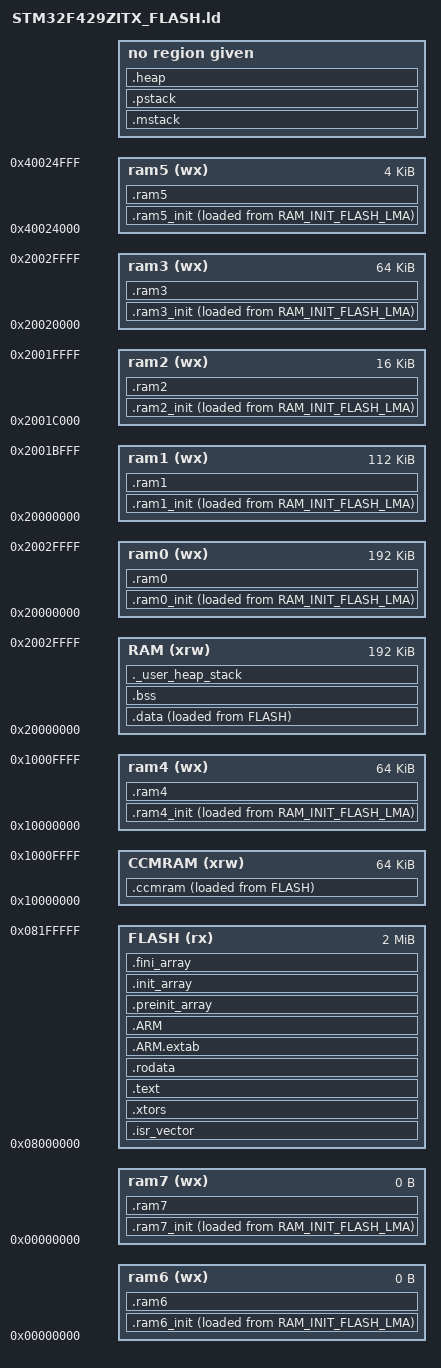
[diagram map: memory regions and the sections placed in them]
/*
******************************************************************************
**
** @file        : LinkerScript.ld
**
** @author      : Auto-generated by STM32CubeIDE
**
**  Abstract    : Linker script for NUCLEO-F429ZI Board embedding STM32F429ZITx Device from stm32f4 series
**                      2048Kbytes FLASH
**                      64Kbytes CCMRAM
**                      192Kbytes RAM
**
**                Set heap size, stack size and stack location according
**                to application requirements.
**
**                Set memory bank area and size if external memory is used
**
**  Target      : STMicroelectronics STM32
**
**  Distribution: The file is distributed as is, without any warranty
**                of any kind.
**
******************************************************************************
** @attention
**
** Copyright (c) 2023 STMicroelectronics.
** All rights reserved.
**
** This software is licensed under terms that can be found in the LICENSE file
** in the root directory of this software component.
** If no LICENSE file comes with this software, it is provided AS-IS.
**
******************************************************************************
*/

/* Entry Point */
ENTRY(Reset_Handler)

/* Highest address of the user mode stack */
_estack = ORIGIN(RAM) + LENGTH(RAM); /* end of "RAM" Ram type memory */

_Min_Heap_Size = 0x200 ; /* required amount of heap */
_Min_Stack_Size = 0x400 ; /* required amount of stack */

/* Memories definition */
MEMORY
{
  CCMRAM    (xrw)    : ORIGIN = 0x10000000,   LENGTH = 64K
  RAM    (xrw)    : ORIGIN = 0x20000000,   LENGTH = 192K
  FLASH    (rx)    : ORIGIN = 0x8000000,   LENGTH = 2048K
  ram0   (wx) : org = 0x20000000, len = 192k    /* SRAM1 + SRAM2 + SRAM3 */
    ram1   (wx) : org = 0x20000000, len = 112k    /* SRAM1 */
    ram2   (wx) : org = 0x2001C000, len = 16k     /* SRAM2 */
    ram3   (wx) : org = 0x20020000, len = 64k     /* SRAM3 */
    ram4   (wx) : org = 0x10000000, len = 64k     /* CCM SRAM */
    ram5   (wx) : org = 0x40024000, len = 4k      /* BCKP SRAM */
    ram6   (wx) : org = 0x00000000, len = 0
    ram7   (wx) : org = 0x00000000, len = 0
}

/* Sections */
SECTIONS
{
  /* The startup code into "FLASH" Rom type memory */
  .isr_vector :
  {
    . = ALIGN(4);
    KEEP(*(.isr_vector)) /* Startup code */
    . = ALIGN(4);
  } >FLASH

  .xtors : ALIGN(4)
  {
    __init_array_base__ = .;
    KEEP(*(SORT(.init_array.*)))
    KEEP(*(.init_array))
    __init_array_end__ = .;
    __fini_array_base__ = .;
    KEEP(*(.fini_array))
    KEEP(*(SORT(.fini_array.*)))
    __fini_array_end__ = .;
  } > FLASH AT > FLASH
  /* The program code and other data into "FLASH" Rom type memory */
  .text :
  {
    . = ALIGN(4);
    *(.text)           /* .text sections (code) */
    *(.text*)          /* .text* sections (code) */
    *(.glue_7)         /* glue arm to thumb code */
    *(.glue_7t)        /* glue thumb to arm code */
    *(.eh_frame)

    KEEP (*(.init))
    KEEP (*(.fini))

    . = ALIGN(4);
    _etext = .;        /* define a global symbols at end of code */
  } >FLASH

  /* Constant data into "FLASH" Rom type memory */
  .rodata :
  {
    . = ALIGN(4);
    *(.rodata)         /* .rodata sections (constants, strings, etc.) */
    *(.rodata*)        /* .rodata* sections (constants, strings, etc.) */
    . = ALIGN(4);
  } >FLASH

  .ARM.extab   : {
    . = ALIGN(4);
    *(.ARM.extab* .gnu.linkonce.armextab.*)
    . = ALIGN(4);
  } >FLASH

  .ARM : {
    . = ALIGN(4);
    __exidx_start = .;
    *(.ARM.exidx*)
    __exidx_end = .;
    . = ALIGN(4);
  } >FLASH

  .preinit_array     :
  {
    . = ALIGN(4);
    PROVIDE_HIDDEN (__preinit_array_start = .);
    KEEP (*(.preinit_array*))
    PROVIDE_HIDDEN (__preinit_array_end = .);
    . = ALIGN(4);
  } >FLASH

  .init_array :
  {
    . = ALIGN(4);
    PROVIDE_HIDDEN (__init_array_start = .);
    KEEP (*(SORT(.init_array.*)))
    KEEP (*(.init_array*))
    PROVIDE_HIDDEN (__init_array_end = .);
    . = ALIGN(4);
  } >FLASH

  .fini_array :
  {
    . = ALIGN(4);
    PROVIDE_HIDDEN (__fini_array_start = .);
    KEEP (*(SORT(.fini_array.*)))
    KEEP (*(.fini_array*))
    PROVIDE_HIDDEN (__fini_array_end = .);
    . = ALIGN(4);
  } >FLASH

  /* Used by the startup to initialize data */
  _sidata = LOADADDR(.data);

  .mstack (NOLOAD) :
    {
        . = ALIGN(8);
        __main_stack_base__ = .;
        . += __main_stack_size__;
        . = ALIGN(8);
        __main_stack_end__ = .;
    } > MAIN_STACK_RAM

    /* Special section for process stack.*/
    .pstack (NOLOAD) :
    {
        . = ALIGN(8);
        __process_stack_base__ = .;
        __main_thread_stack_base__ = .;
        . += __process_stack_size__;
        . = ALIGN(8);
        __process_stack_end__ = .;
        __main_thread_stack_end__ = .;
    } > PROCESS_STACK_RAM
    
  /* Initialized data sections into "RAM" Ram type memory */
  .data :
  {
    . = ALIGN(4);
    _sdata = .;        /* create a global symbol at data start */
    __textdata_base__ = LOADADDR(.data);
    __data_base__ = .;
    *(.data)           /* .data sections */
    *(.data*)          /* .data* sections */
    *(.RamFunc)        /* .RamFunc sections */
    *(.RamFunc*)       /* .RamFunc* sections */

    . = ALIGN(4);
    __data_end__ = .;
    _edata = .;        /* define a global symbol at data end */

  } >RAM AT> FLASH

  _siccmram = LOADADDR(.ccmram);

  /* CCM-RAM section
  *
  * IMPORTANT NOTE!
  * If initialized variables will be placed in this section,
  * the startup code needs to be modified to copy the init-values.
  */
  .ccmram :
  {
    . = ALIGN(4);
    _sccmram = .;       /* create a global symbol at ccmram start */
    *(.ccmram)
    *(.ccmram*)

    . = ALIGN(4);
    _eccmram = .;       /* create a global symbol at ccmram end */
  } >CCMRAM AT> FLASH

  /* Uninitialized data section into "RAM" Ram type memory */
  . = ALIGN(4);
  .bss :
  {
    /* This is used by the startup in order to initialize the .bss section */
    _sbss = .;         /* define a global symbol at bss start */
    __bss_start__ = _sbss;
    __bss_base__ = .;
    *(.bss)
    *(.bss*)
    *(COMMON)

    . = ALIGN(4);
    _ebss = .;         /* define a global symbol at bss end */
    __bss_end__ = _ebss;
  } >RAM

  /* User_heap_stack section, used to check that there is enough "RAM" Ram  type memory left */
  ._user_heap_stack :
  {
    . = ALIGN(8);
    PROVIDE ( end = . );
    PROVIDE ( _end = . );
    . = . + _Min_Heap_Size;
    . = . + _Min_Stack_Size;
    . = ALIGN(8);
  } >RAM

	.heap (NOLOAD) :
    {
        . = ALIGN(8);
        __heap_base__ = .;
        . = ORIGIN(HEAP_RAM) + LENGTH(HEAP_RAM);
        __heap_end__ = .;
    } > HEAP_RAM
    
    .ram0_init : ALIGN(4)
    {
        __ram0_init_text__ = LOADADDR(.ram0_init);
        __ram0_init__ = .;
        KEEP(*(.ram0_init))
        KEEP(*(.ram0_init.*))
        . = ALIGN(4);
    } > ram0 AT > RAM_INIT_FLASH_LMA

    .ram0 (NOLOAD) : ALIGN(4)
    {
        __ram0_clear__ = .;
        *(.ram0_clear)
        *(.ram0_clear.*)
        . = ALIGN(4);
        __ram0_noinit__ = .;
        *(.ram0)
        *(.ram0.*)
        . = ALIGN(4);
        __ram0_free__ = .;
    } > ram0

    .ram1_init : ALIGN(4)
    {
        __ram1_init_text__ = LOADADDR(.ram1_init);
        __ram1_init__ = .;
        KEEP(*(.ram1_init))
        KEEP(*(.ram1_init.*))
        . = ALIGN(4);
    } > ram1 AT > RAM_INIT_FLASH_LMA

    .ram1 (NOLOAD) : ALIGN(4)
    {
        __ram1_clear__ = .;
        *(.ram1_clear)
        *(.ram1_clear.*)
        . = ALIGN(4);
        __ram1_noinit__ = .;
        *(.ram1)
        *(.ram1.*)
        . = ALIGN(4);
        __ram1_free__ = .;
    } > ram1

    .ram2_init : ALIGN(4)
    {
        __ram2_init_text__ = LOADADDR(.ram2_init);
        __ram2_init__ = .;
        KEEP(*(.ram2_init))
        KEEP(*(.ram2_init.*))
        . = ALIGN(4);
    } > ram2 AT > RAM_INIT_FLASH_LMA

    .ram2 (NOLOAD) : ALIGN(4)
    {
        __ram2_clear__ = .;
        *(.ram2_clear)
        *(.ram2_clear.*)
        . = ALIGN(4);
        __ram2_noinit__ = .;
        *(.ram2)
        *(.ram2.*)
        . = ALIGN(4);
        __ram2_free__ = .;
    } > ram2

    .ram3_init : ALIGN(4)
    {
        __ram3_init_text__ = LOADADDR(.ram3_init);
        __ram3_init__ = .;
        KEEP(*(.ram3_init))
        KEEP(*(.ram3_init.*))
        . = ALIGN(4);
    } > ram3 AT > RAM_INIT_FLASH_LMA

    .ram3 (NOLOAD) : ALIGN(4)
    {
        __ram3_clear__ = .;
        *(.ram3_clear)
        *(.ram3_clear.*)
        . = ALIGN(4);
        __ram3_noinit__ = .;
        *(.ram3)
        *(.ram3.*)
        . = ALIGN(4);
        __ram3_free__ = .;
    } > ram3

    .ram4_init : ALIGN(4)
    {
        __ram4_init_text__ = LOADADDR(.ram4_init);
        __ram4_init__ = .;
        KEEP(*(.ram4_init))
        KEEP(*(.ram4_init.*))
        . = ALIGN(4);
    } > ram4 AT > RAM_INIT_FLASH_LMA

    .ram4 (NOLOAD) : ALIGN(4)
    {
        __ram4_clear__ = .;
        *(.ram4_clear)
        *(.ram4_clear.*)
        . = ALIGN(4);
        __ram4_noinit__ = .;
        *(.ram4)
        *(.ram4.*)
        . = ALIGN(4);
        __ram4_free__ = .;
    } > ram4

    .ram5_init : ALIGN(4)
    {
        __ram5_init_text__ = LOADADDR(.ram5_init);
        __ram5_init__ = .;
        KEEP(*(.ram5_init))
        KEEP(*(.ram5_init.*))
        . = ALIGN(4);
    } > ram5 AT > RAM_INIT_FLASH_LMA

    .ram5 (NOLOAD) : ALIGN(4)
    {
        __ram5_clear__ = .;
        *(.ram5_clear)
        *(.ram5_clear.*)
        . = ALIGN(4);
        __ram5_noinit__ = .;
        *(.ram5)
        *(.ram5.*)
        . = ALIGN(4);
        __ram5_free__ = .;
    } > ram5

    .ram6_init : ALIGN(4)
    {
        __ram6_init_text__ = LOADADDR(.ram6_init);
        __ram6_init__ = .;
        KEEP(*(.ram6_init))
        KEEP(*(.ram6_init.*))
        . = ALIGN(4);
    } > ram6 AT > RAM_INIT_FLASH_LMA

    .ram6 (NOLOAD) : ALIGN(4)
    {
        __ram6_clear__ = .;
        *(.ram6_clear)
        *(.ram6_clear.*)
        . = ALIGN(4);
        __ram6_noinit__ = .;
        *(.ram6)
        *(.ram6.*)
        . = ALIGN(4);
        __ram6_free__ = .;
    } > ram6

    .ram7_init : ALIGN(4)
    {
        __ram7_init_text__ = LOADADDR(.ram7_init);
        __ram7_init__ = .;
        KEEP(*(.ram7_init))
        KEEP(*(.ram7_init.*))
        . = ALIGN(4);
    } > ram7 AT > RAM_INIT_FLASH_LMA

    .ram7 (NOLOAD) : ALIGN(4)
    {
        __ram7_clear__ = .;
        *(.ram7_clear)
        *(.ram7_clear.*)
        . = ALIGN(4);
        __ram7_noinit__ = .;
        *(.ram7)
        *(.ram7.*)
        . = ALIGN(4);
        __ram7_free__ = .;
    } > ram7
    
  /* Remove information from the compiler libraries */
  /DISCARD/ :
  {
    libc.a ( * )
    libm.a ( * )
    libgcc.a ( * )
  }

  .ARM.attributes 0 : { *(.ARM.attributes) }
}
